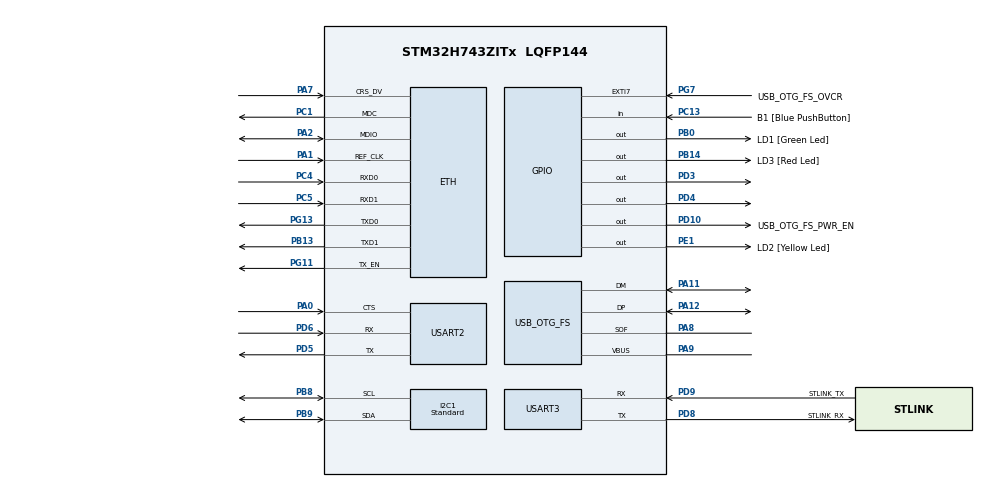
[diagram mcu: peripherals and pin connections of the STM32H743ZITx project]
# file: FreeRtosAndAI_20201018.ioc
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CORTEX_M7.CPU_DCache=Enabled
CORTEX_M7.CPU_ICache=Enabled
ETH.MediaInterface=HAL_ETH_RMII_MODE
FREERTOS.Tasks01=defaultTask,0,128,StartDefaultTask,Default,NULL,Dynamic,NULL,NULL;myTask02,-3,128,StartTask02,Default,NULL,Dynamic,NULL,NULL;myTask03,-3,128,StartTask03,Default,NULL,Dynamic,NULL,NULL
I2C1.I2C_Speed_Mode=I2C_Standard
I2C1.Timing=0x307075B1
Mcu.Family=STM32H7
Mcu.Name=STM32H743ZITx
Mcu.Package=LQFP144
NVIC.PriorityGroup=NVIC_PRIORITYGROUP_4
NVIC.TIM1_UP_IRQn=true\:0\:0\:false\:false\:true\:false\:false\:true
NVIC.TimeBase=TIM1_UP_IRQn
NVIC.TimeBaseIP=TIM1
PA0.Mode=CTS_Only
PA0.Signal=USART2_CTS
PA1.Mode=RMII
PA1.Signal=ETH_REF_CLK
PA11.Mode=Device_Only
PA11.Signal=USB_OTG_FS_DM
PA12.Mode=Device_Only
PA12.Signal=USB_OTG_FS_DP
PA2.Mode=RMII
PA2.Signal=ETH_MDIO
PA7.Mode=RMII
PA7.Signal=ETH_CRS_DV
PA8.Mode=Activate_SOF_FS
PA8.Signal=USB_OTG_FS_SOF
PA9.Mode=Activate_VBUS
PA9.Signal=USB_OTG_FS_VBUS
PB0.GPIO_Label=LD1 [Green Led]
PB0.Signal=GPIO_Output
PB13.Mode=RMII
PB13.Signal=ETH_TXD1
PB14.GPIO_Label=LD3 [Red Led]
PB14.Signal=GPIO_Output
PB8.Mode=I2C
PB8.Signal=I2C1_SCL
PB9.Mode=I2C
PB9.Signal=I2C1_SDA
PC1.Mode=RMII
PC1.Signal=ETH_MDC
PC13.GPIO_Label=B1 [Blue PushButton]
PC13.Signal=GPIO_Input
PC14-OSC32_IN\ (OSC32_IN).Mode=LSE-External-Oscillator
PC14-OSC32_IN\ (OSC32_IN).Signal=RCC_OSC32_IN
PC15-OSC32_OUT\ (OSC32_OUT).Mode=LSE-External-Oscillator
PC15-OSC32_OUT\ (OSC32_OUT).Signal=RCC_OSC32_OUT
PC4.Mode=RMII
PC4.Signal=ETH_RXD0
PC5.Mode=RMII
PC5.Signal=ETH_RXD1
PD10.GPIO_Label=USB_OTG_FS_PWR_EN
PD10.Signal=GPIO_Output
PD3.PinState=GPIO_PIN_SET
PD3.Signal=GPIO_Output
PD4.Signal=GPIO_Output
PD5.Mode=Asynchronous
PD5.Signal=USART2_TX
PD6.Mode=Asynchronous
PD6.Signal=USART2_RX
PD8.GPIO_Label=STLINK_RX
PD8.Mode=Asynchronous
PD8.Signal=USART3_TX
PD9.GPIO_Label=STLINK_TX
PD9.Mode=Asynchronous
PD9.Signal=USART3_RX
PE1.GPIO_Label=LD2 [Yellow Led]
PE1.Signal=GPIO_Output
PG11.Mode=RMII
PG11.Signal=ETH_TX_EN
PG13.Mode=RMII
PG13.Signal=ETH_TXD0
PG7.GPIO_Label=USB_OTG_FS_OVCR
PG7.Signal=GPXTI7
PH0-OSC_IN\ (PH0).Mode=HSE-External-Clock-Source
PH0-OSC_IN\ (PH0).Signal=RCC_OSC_IN
PH1-OSC_OUT\ (PH1).Signal=RCC_OSC_OUT
ProjectManager.HeapSize=0x2000
ProjectManager.StackSize=0x800
ProjectManager.TargetToolchain=STM32CubeIDE
RCC.ADCFreq_Value=16125000
RCC.APB1Freq_Value=120000000
RCC.APB2Freq_Value=120000000
RCC.APB3Freq_Value=120000000
RCC.APB4Freq_Value=120000000
RCC.CortexFreq_Value=480000000
RCC.D1PPRE=RCC_APB3_DIV2
RCC.D2PPRE1=RCC_APB1_DIV2
RCC.D2PPRE2=RCC_APB2_DIV2
RCC.D3PPRE=RCC_APB4_DIV2
RCC.DIVM1=1
RCC.DIVN1=120
RCC.DIVQ1=20
RCC.HCLKFreq_Value=240000000
RCC.HPRE=RCC_HCLK_DIV2
RCC.HSE_VALUE=8000000
RCC.PLLFRACN=0
RCC.SYSCLKFreq_VALUE=480000000
RCC.SYSCLKSource=RCC_SYSCLKSOURCE_PLLCLK
RCC.USBFreq_Value=48000000
STMicroelectronics.X-CUBE-AI.5.1.2.ActivationBufferSizeList=468
STMicroelectronics.X-CUBE-AI.5.1.2.ApplicationCcArtificialOoIntelligenceJjApplication=ApplicationTemplate
STMicroelectronics.X-CUBE-AI.5.1.2.HeapSize=0x2000
STMicroelectronics.X-CUBE-AI.5.1.2.InternalRamActivationBufferMaxSize=AI_NETWORK_DATA_ACTIVATIONS_SIZE
STMicroelectronics.X-CUBE-AI.5.1.2.LatestDirectoryUsed-eb425495237ff17701dc50f888ce918dccc7f03fca3647c043469d400bd4a8f3=D\:\\Py Project\\NN\\Keras
STMicroelectronics.X-CUBE-AI.5.1.2.MaximumNumberOfInputLayer=1
STMicroelectronics.X-CUBE-AI.5.1.2.MaximumNumberOfOutputLayer=1
STMicroelectronics.X-CUBE-AI.5.1.2.MaximumSizeOfInputLayer=AI_NETWORK_IN_1_SIZE_BYTES
STMicroelectronics.X-CUBE-AI.5.1.2.MaximumSizeOfOutputLayer=AI_NETWORK_OUT_1_SIZE_BYTES
STMicroelectronics.X-CUBE-AI.5.1.2.ModelActualCompression-eb425495237ff17701dc50f888ce918dccc7f03fca3647c043469d400bd4a8f3=0.0
STMicroelectronics.X-CUBE-AI.5.1.2.ModelCompression-eb425495237ff17701dc50f888ce918dccc7f03fca3647c043469d400bd4a8f3=1
STMicroelectronics.X-CUBE-AI.5.1.2.ModelFlashOccupation-eb425495237ff17701dc50f888ce918dccc7f03fca3647c043469d400bd4a8f3=10772
STMicroelectronics.X-CUBE-AI.5.1.2.ModelHashList=eb425495237ff17701dc50f888ce918dccc7f03fca3647c043469d400bd4a8f3
STMicroelectronics.X-CUBE-AI.5.1.2.ModelKind-eb425495237ff17701dc50f888ce918dccc7f03fca3647c043469d400bd4a8f3=KERAS
STMicroelectronics.X-CUBE-AI.5.1.2.ModelMacc-eb425495237ff17701dc50f888ce918dccc7f03fca3647c043469d400bd4a8f3=2763
STMicroelectronics.X-CUBE-AI.5.1.2.ModelName-eb425495237ff17701dc50f888ce918dccc7f03fca3647c043469d400bd4a8f3=network
STMicroelectronics.X-CUBE-AI.5.1.2.ModelNameList=network
STMicroelectronics.X-CUBE-AI.5.1.2.ModelRamOccupation-eb425495237ff17701dc50f888ce918dccc7f03fca3647c043469d400bd4a8f3=468
STMicroelectronics.X-CUBE-AI.5.1.2.ModelStructureFile-eb425495237ff17701dc50f888ce918dccc7f03fca3647c043469d400bd4a8f3=D\:\\Py Project\\NN\\Keras\\myHandRec20201015.h5
STMicroelectronics.X-CUBE-AI.5.1.2.ModelType-eb425495237ff17701dc50f888ce918dccc7f03fca3647c043469d400bd4a8f3=Saved model
STMicroelectronics.X-CUBE-AI.5.1.2.StackSize=0x800
STMicroelectronics.X-CUBE-AI.5.1.2.WorkingBufferStartAddrList=0xFFFFFFFF
STMicroelectronics.X-CUBE-AI.5.1.2.XAaCUBEAaAICcArtificialOoIntelligenceJjCore=true
USART2.SwapParam=ADVFEATURE_SWAP_ENABLE
USART2.VirtualMode-Asynchronous=VM_ASYNC
USART3.VirtualMode-Asynchronous=VM_ASYNC
USB_OTG_FS.VirtualMode=Device_Only
VP_CRC_VS_CRC.Mode=CRC_Activate
VP_FREERTOS_VS_CMSIS_V1.Mode=CMSIS_V1
VP_STMicroelectronics.X-CUBE-AI_VS_ArtificialOoIntelligenceJjApplication_5.1.2.Mode=ArtificialOoIntelligenceJjApplication
VP_STMicroelectronics.X-CUBE-AI_VS_ArtificialOoIntelligenceJjXAaCUBEAaAI_5.1.2.Mode=ArtificialOoIntelligenceJjXAaCUBEAaAI
VP_SYS_VS_tim1.Mode=TIM1
board=NUCLEO-H743ZI2

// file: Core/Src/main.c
/* USER CODE BEGIN Header */
/**
  ******************************************************************************
  * @file           : main.c
  * @brief          : Main program body
  ******************************************************************************
  * @attention
  *
  * <h2><center>&copy; Copyright (c) 2020 STMicroelectronics.
  * All rights reserved.</center></h2>
  *
  * This software component is licensed by ST under BSD 3-Clause license,
  * the "License"; You may not use this file except in compliance with the
  * License. You may obtain a copy of the License at:
  *                        opensource.org/licenses/BSD-3-Clause
  *
  ******************************************************************************
  */
/* USER CODE END Header */
#include "main.h"
#include "cmsis_os.h"
#include "crc.h"
#include "eth.h"
#include "i2c.h"
#include "usart.h"
#include "usb_otg.h"
#include "gpio.h"
#include "app_x-cube-ai.h"

void SystemClock_Config(void);
void MX_FREERTOS_Init(void);

int main(void)
{

  /* Enable I-Cache---------------------------------------------------------*/
  SCB_EnableICache();

  /* Enable D-Cache---------------------------------------------------------*/
  SCB_EnableDCache();

  /* MCU Configuration--------------------------------------------------------*/

  /* Reset of all peripherals, Initializes the Flash interface and the Systick. */
  HAL_Init();

  /* Configure the system clock */
  SystemClock_Config();

  /* Initialize all configured peripherals */
  MX_GPIO_Init();
  MX_ETH_Init();
  MX_USART3_UART_Init();
  MX_USB_OTG_FS_PCD_Init();
  MX_CRC_Init();
  MX_I2C1_Init();
  MX_USART2_UART_Init();
  MX_X_CUBE_AI_Init();

  /* Call init function for freertos objects (in freertos.c) */
  MX_FREERTOS_Init();
  /* Start scheduler */
  osKernelStart();

  /* We should never get here as control is now taken by the scheduler */
  /* Infinite loop */
  while (1)
  {

  }
}

void SystemClock_Config(void)
{
  RCC_OscInitTypeDef RCC_OscInitStruct = {0};
  RCC_ClkInitTypeDef RCC_ClkInitStruct = {0};
  RCC_PeriphCLKInitTypeDef PeriphClkInitStruct = {0};

  /** Supply configuration update enable
  */
  HAL_PWREx_ConfigSupply(PWR_LDO_SUPPLY);
  /** Configure the main internal regulator output voltage
  */
  __HAL_PWR_VOLTAGESCALING_CONFIG(PWR_REGULATOR_VOLTAGE_SCALE0);

  while(!__HAL_PWR_GET_FLAG(PWR_FLAG_VOSRDY)) {}
  /** Initializes the RCC Oscillators according to the specified parameters
  * in the RCC_OscInitTypeDef structure.
  */
  RCC_OscInitStruct.OscillatorType = RCC_OSCILLATORTYPE_HSE;
  RCC_OscInitStruct.HSEState = RCC_HSE_BYPASS;
  RCC_OscInitStruct.PLL.PLLState = RCC_PLL_ON;
  RCC_OscInitStruct.PLL.PLLSource = RCC_PLLSOURCE_HSE;
  RCC_OscInitStruct.PLL.PLLM = 1;
  RCC_OscInitStruct.PLL.PLLN = 120;
  RCC_OscInitStruct.PLL.PLLP = 2;
  RCC_OscInitStruct.PLL.PLLQ = 20;
  RCC_OscInitStruct.PLL.PLLR = 2;
  RCC_OscInitStruct.PLL.PLLRGE = RCC_PLL1VCIRANGE_3;
  RCC_OscInitStruct.PLL.PLLVCOSEL = RCC_PLL1VCOWIDE;
  RCC_OscInitStruct.PLL.PLLFRACN = 0;
  if (HAL_RCC_OscConfig(&RCC_OscInitStruct) != HAL_OK)
  {
    Error_Handler();
  }
  /** Initializes the CPU, AHB and APB buses clocks
  */
  RCC_ClkInitStruct.ClockType = RCC_CLOCKTYPE_HCLK|RCC_CLOCKTYPE_SYSCLK
                              |RCC_CLOCKTYPE_PCLK1|RCC_CLOCKTYPE_PCLK2
                              |RCC_CLOCKTYPE_D3PCLK1|RCC_CLOCKTYPE_D1PCLK1;
  RCC_ClkInitStruct.SYSCLKSource = RCC_SYSCLKSOURCE_PLLCLK;
  RCC_ClkInitStruct.SYSCLKDivider = RCC_SYSCLK_DIV1;
  RCC_ClkInitStruct.AHBCLKDivider = RCC_HCLK_DIV2;
  RCC_ClkInitStruct.APB3CLKDivider = RCC_APB3_DIV2;
  RCC_ClkInitStruct.APB1CLKDivider = RCC_APB1_DIV2;
  RCC_ClkInitStruct.APB2CLKDivider = RCC_APB2_DIV2;
  RCC_ClkInitStruct.APB4CLKDivider = RCC_APB4_DIV2;

  if (HAL_RCC_ClockConfig(&RCC_ClkInitStruct, FLASH_LATENCY_4) != HAL_OK)
  {
    Error_Handler();
  }
  PeriphClkInitStruct.PeriphClockSelection = RCC_PERIPHCLK_USART3|RCC_PERIPHCLK_USART2
                              |RCC_PERIPHCLK_I2C1|RCC_PERIPHCLK_USB;
  PeriphClkInitStruct.Usart234578ClockSelection = RCC_USART234578CLKSOURCE_D2PCLK1;
  PeriphClkInitStruct.I2c123ClockSelection = RCC_I2C123CLKSOURCE_D2PCLK1;
  PeriphClkInitStruct.UsbClockSelection = RCC_USBCLKSOURCE_PLL;
  if (HAL_RCCEx_PeriphCLKConfig(&PeriphClkInitStruct) != HAL_OK)
  {
    Error_Handler();
  }
  /** Enable USB Voltage detector
  */
  HAL_PWREx_EnableUSBVoltageDetector();
}

void HAL_TIM_PeriodElapsedCallback(TIM_HandleTypeDef *htim)
{
  if (htim->Instance == TIM1) {
    HAL_IncTick();
  }
}

void Error_Handler(void)
{
}

/************************ (C) COPYRIGHT STMicroelectronics *****END OF FILE****/

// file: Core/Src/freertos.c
/* USER CODE BEGIN Header */
/**
  ******************************************************************************
  * File Name          : freertos.c
  * Description        : Code for freertos applications
  ******************************************************************************
  * @attention
  *
  * <h2><center>&copy; Copyright (c) 2020 STMicroelectronics.
  * All rights reserved.</center></h2>
  *
  * This software component is licensed by ST under Ultimate Liberty license
  * SLA0044, the "License"; You may not use this file except in compliance with
  * the License. You may obtain a copy of the License at:
  *                             www.st.com/SLA0044
  *
  ******************************************************************************
  */
/* USER CODE END Header */

#include "FreeRTOS.h"
#include "task.h"
#include "main.h"
#include "cmsis_os.h"

/* USER CODE BEGIN Includes */
#include "app_x-cube-ai.h"
#include "MyNetAPI.h"
/* USER CODE END Includes */

osThreadId defaultTaskHandle;
osThreadId myTask02Handle;
osThreadId myTask03Handle;

void StartDefaultTask(void const * argument);
void StartTask02(void const * argument);
void StartTask03(void const * argument);

void MX_FREERTOS_Init(void); /* (MISRA C 2004 rule 8.1) */

/* GetIdleTaskMemory prototype (linked to static allocation support) */
void vApplicationGetIdleTaskMemory( StaticTask_t **ppxIdleTaskTCBBuffer, StackType_t **ppxIdleTaskStackBuffer, uint32_t *pulIdleTaskStackSize );

/* USER CODE BEGIN GET_IDLE_TASK_MEMORY */
static StaticTask_t xIdleTaskTCBBuffer;
static StackType_t xIdleStack[configMINIMAL_STACK_SIZE];

void vApplicationGetIdleTaskMemory( StaticTask_t **ppxIdleTaskTCBBuffer, StackType_t **ppxIdleTaskStackBuffer, uint32_t *pulIdleTaskStackSize )
{
  *ppxIdleTaskTCBBuffer = &xIdleTaskTCBBuffer;
  *ppxIdleTaskStackBuffer = &xIdleStack[0];
  *pulIdleTaskStackSize = configMINIMAL_STACK_SIZE;
  /* place for user code */
}
/* USER CODE END GET_IDLE_TASK_MEMORY */

void MX_FREERTOS_Init(void) {

  /* Create the thread(s) */
  /* definition and creation of defaultTask */
  osThreadDef(defaultTask, StartDefaultTask, osPriorityNormal, 0, 128);
  defaultTaskHandle = osThreadCreate(osThread(defaultTask), NULL);

  /* definition and creation of myTask02 */
  osThreadDef(myTask02, StartTask02, osPriorityIdle, 0, 128);
  myTask02Handle = osThreadCreate(osThread(myTask02), NULL);

  /* definition and creation of myTask03 */
  osThreadDef(myTask03, StartTask03, osPriorityIdle, 0, 128);
  myTask03Handle = osThreadCreate(osThread(myTask03), NULL);

}

void StartDefaultTask(void const * argument)
{
  /* USER CODE BEGIN StartDefaultTask */
  /* Infinite loop */
  for(;;)
  {
	  HAL_GPIO_TogglePin(LD1_GPIO_Port, LD1_Pin);
	  MX_X_CUBE_AI_Process();
	  HandRecResultPrint();
	  osDelay(100);
  }
  /* USER CODE END StartDefaultTask */
}

void StartTask02(void const * argument)
{
  /* USER CODE BEGIN StartTask02 */
  /* Infinite loop */
  for(;;)
  {
	  uint8_t data_to_send[3] = {0xAA, (uint8_t)XBQ_HandRec.result, 0x55};
	  HAL_GPIO_TogglePin(LD2_GPIO_Port, LD2_Pin);
	  HAL_UART_Transmit(&huart2, &data_to_send, 3, HAL_MAX_DELAY);
	  osDelay(500);
  }
  /* USER CODE END StartTask02 */
}

void StartTask03(void const * argument)
{
  /* USER CODE BEGIN StartTask03 */
  /* Infinite loop */
  for(;;)
  {
	  osDelay(1000);
  }
  /* USER CODE END StartTask03 */
}

/************************ (C) COPYRIGHT STMicroelectronics *****END OF FILE****/
